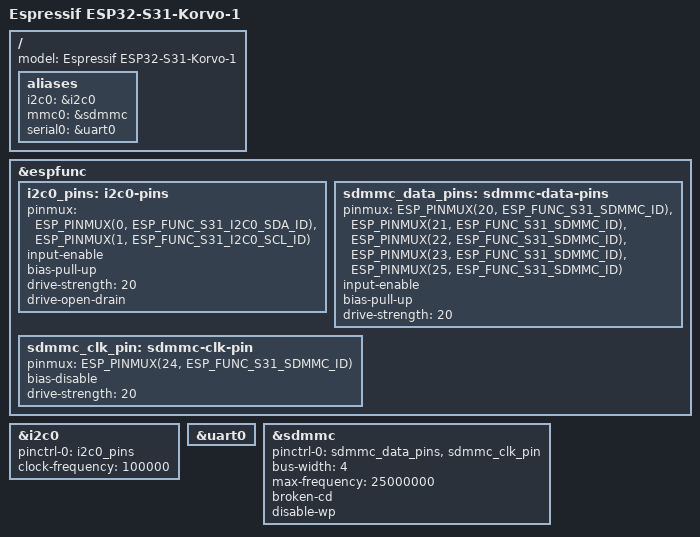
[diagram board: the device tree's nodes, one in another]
// SPDX-License-Identifier: (GPL-2.0 OR MIT)
/*
 * Espressif ESP32-S31-Korvo-1 board-level description.
 *
 * Keep physical wiring, pin assignments, model, aliases and permanently
 * fitted peripheral enablement here.
 *
 * SoC-invariant resources belong in esp32s31.dtsi; use-case- and
 * test-specific changes belong in .dtso overlays.
 */

/dts-v1/;

#include "esp32s31.dtsi"

/ {
	model = "Espressif ESP32-S31-Korvo-1";

	aliases {
		i2c0 = &i2c0;
		mmc0 = &sdmmc;
		serial0 = &uart0;
	};
};

&espfunc {
	/* I2C0: SDA on GPIO0 and SCL on GPIO1. */
	i2c0_pins: i2c0-pins {
		pinmux = <ESP_PINMUX(0, ESP_FUNC_S31_I2C0_SDA_ID)>,
			 <ESP_PINMUX(1, ESP_FUNC_S31_I2C0_SCL_ID)>;

		input-enable;
		bias-pull-up;
		drive-strength = <20>;
		drive-open-drain;
	};

	sdmmc_data_pins: sdmmc-data-pins {
		pinmux = <ESP_PINMUX(20, ESP_FUNC_S31_SDMMC_ID)>,
			 <ESP_PINMUX(21, ESP_FUNC_S31_SDMMC_ID)>,
			 <ESP_PINMUX(22, ESP_FUNC_S31_SDMMC_ID)>,
			 <ESP_PINMUX(23, ESP_FUNC_S31_SDMMC_ID)>,
			 <ESP_PINMUX(25, ESP_FUNC_S31_SDMMC_ID)>;

		input-enable;
		bias-pull-up;
		drive-strength = <20>;
	};

	sdmmc_clk_pin: sdmmc-clk-pin {
		pinmux = <ESP_PINMUX(24, ESP_FUNC_S31_SDMMC_ID)>;

		bias-disable;
		drive-strength = <20>;
	};
};

&i2c0 {
	pinctrl-names = "default";
	pinctrl-0 = <&i2c0_pins>;
	clock-frequency = <100000>;
	status = "okay";
};

&uart0 {
	status = "okay";
};

&sdmmc {
	pinctrl-names = "default";
	pinctrl-0 = <&sdmmc_data_pins>, <&sdmmc_clk_pin>;
	bus-width = <4>;
	/* SD Default Speed mode supports up to 25 MHz. */
	max-frequency = <25000000>;
	broken-cd;
	disable-wp;
	status = "okay";
};
